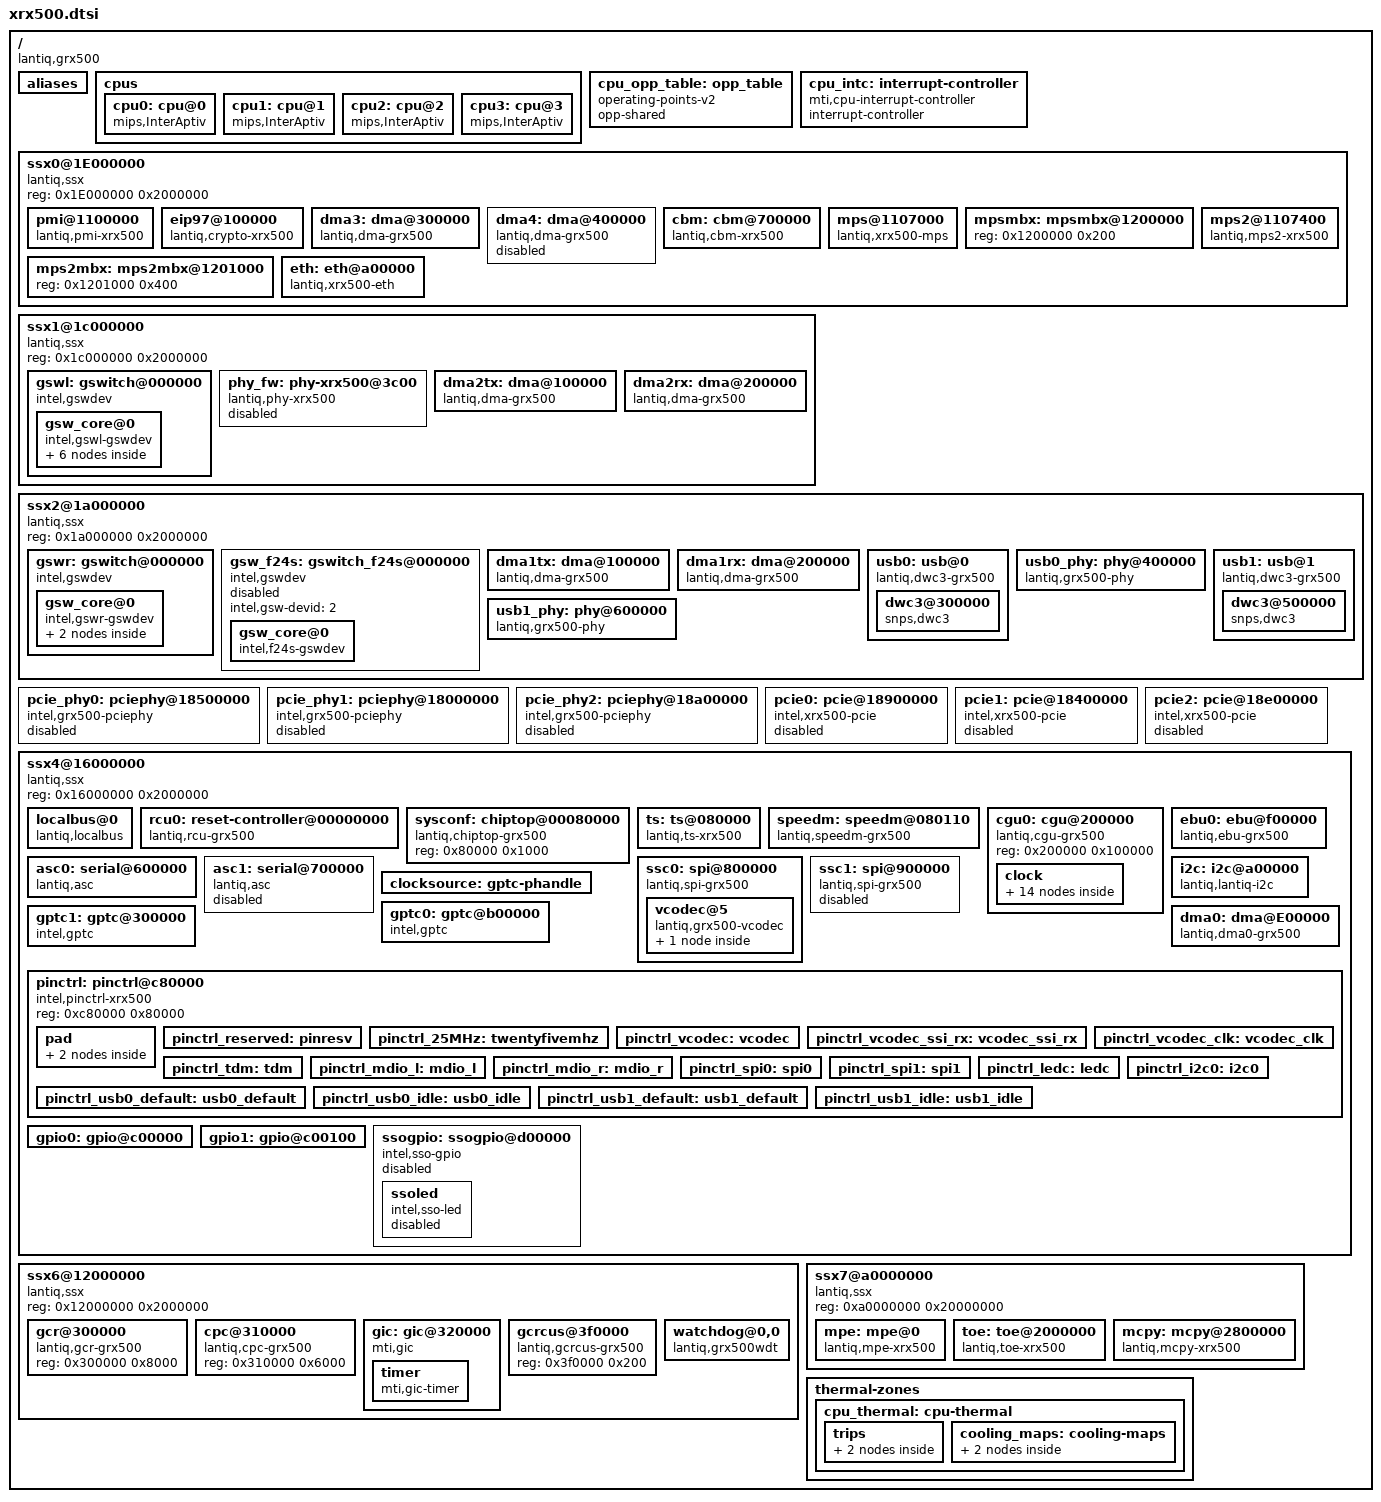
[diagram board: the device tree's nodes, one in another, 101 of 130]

#include <dt-bindings/thermal/thermal.h>

/ {
	#address-cells = <1>;
	#size-cells = <1>;
	compatible = "lantiq,grx500","lantiq,xrx500";

	aliases {
		serial0 = &asc0;
		serial1 = &asc1;
		dma0    = &dma0;
		dma1    = &dma1tx;
		dma2    = &dma1rx;
		dma3    = &dma2tx;
		dma4    = &dma2rx;
		dma5    = &dma3;
		dma6    = &dma4;
		pcie0   = &pcie0;
		pcie1   = &pcie1;
		pcie2   = &pcie2;
		usb0	= &usb0;
		usb1	= &usb1;
		spi1	= &ssc1;
		timer0  = &gptc0;
		timer1  = &gptc1;
		gpio0   = &gpio0;
		gpio1	= &gpio1;
		pciephy0= &pcie_phy0;
		pciephy1= &pcie_phy1;
		pciephy2= &pcie_phy2;
	};

	cpus {
		#address-cells = <1>;
		#size-cells = <0>;

		cpu0: cpu@0 {
			device_type = "cpu";
			compatible = "mips,InterAptiv";
			default-OS = "LINUX";
			clocks = <&cpuclk>;
			clock-names = "cpu";
			clock-latency = <500000>; /* transition latency in ns */
			reg = <0>;
			operating-points-v2 = <&cpu_opp_table>;
			cooling-min-level = <0>;
			cooling-max-level = <2>;
			#cooling-cells = <2>; /* min followed by max */
		};

		cpu1: cpu@1 {
			device_type = "cpu";
			compatible = "mips,InterAptiv";
			default-OS = "LINUX";
			reg = <1>;
			interrupt-parent = <&gic>;
			interrupts = <GIC_SHARED 87 IRQ_TYPE_EDGE_RISING>;
			vmb-fw-ipi = <20>;
			operating-points-v2 = <&cpu_opp_table>;
		};

		cpu2: cpu@2 {
			device_type = "cpu";
			compatible = "mips,InterAptiv";
			default-OS = "LINUX";
			reg = <2>;
			interrupt-parent = <&gic>;
			interrupts = <GIC_SHARED 88 IRQ_TYPE_EDGE_RISING>;
			vmb-fw-ipi = <21>;
			operating-points-v2 = <&cpu_opp_table>;
		};

		cpu3: cpu@3 {
			device_type = "cpu";
			compatible = "mips,InterAptiv";
			default-OS = "LINUX";
			reg = <3>;
			interrupt-parent = <&gic>;
			interrupts = <GIC_SHARED 110 IRQ_TYPE_EDGE_RISING>;
			vmb-fw-ipi = <85>;
			operating-points-v2 = <&cpu_opp_table>;
		};
	};

	cpu_opp_table: opp_table {
		compatible = "operating-points-v2";
		opp-shared;
		/* Define OPPs into a board DTS file */
	};

	cpu_intc: interrupt-controller {
		#address-cells = <0>;
		#interrupt-cells = <1>;
		interrupt-controller;
		compatible = "mti,cpu-interrupt-controller";
	};

	ssx0@1E000000 {
		#address-cells = <1>;
		#size-cells = <1>;
		compatible = "lantiq,ssx", "simple-bus";
		reg = <0x1E000000 0x2000000>;
		ranges = <0x0 0x1E000000 0x02000000>;

		pmi@1100000 {
			compatible = "lantiq,pmi-xrx500";
			reg = <0x1100000 0x100>;
			interrupt-parent = <&gic>;
			interrupts = <GIC_SHARED 94 IRQ_TYPE_LEVEL_HIGH>;
		};

		eip97@100000 {
			compatible = "lantiq,crypto-xrx500";
			reg = <0x100000 0x100000>;
			interrupt-parent = <&gic>;
			interrupts = <GIC_SHARED 89 IRQ_TYPE_LEVEL_HIGH>,
				<GIC_SHARED 90 IRQ_TYPE_LEVEL_HIGH>,
				<GIC_SHARED 91 IRQ_TYPE_LEVEL_HIGH>;
			clocks = <&clkgate1 GATE_EIP97_CLK>;
		};

		dma3: dma@300000 {
			compatible = "lantiq,dma-grx500";
			reg = <0x300000 0x100000>;
			interrupt-parent = <&gic>;
			interrupts = <GIC_SHARED 69 IRQ_TYPE_LEVEL_HIGH>;
			lantiq,dma-pkt-arb = <2>; /* 0 - burst, 1 - mulitburst, 2 - pkt */
			lantiq,dma-burst = <16>; /* 2, 4, 8, 16 */
			lantiq,dma-polling-cnt = <24>;
			lantiq,dma-chan-fc = <0>;
			lantiq,dma-desc-fod = <0>;
			lantiq,dma-desc-in-sram = <1>;
			lantiq,dma-drb = <0>;
			lantiq,dma-byte-en = <1>;
			lantiq,dma-txendi =<3>;
			lantiq,dma-rxendi =<3>;
			lantiq,budget = <20>;
			clocks = <&clkgate1 GATE_TOE_CLK>;
		};

		dma4: dma@400000 {
			status = "disabled";
			compatible = "lantiq,dma-grx500";
			reg = <0x400000 0x100000>;
			interrupt-parent = <&gic>;
			interrupts = <GIC_SHARED 70 IRQ_TYPE_LEVEL_HIGH>;
			lantiq,dma-pkt-arb = <2>; /* 0 - burst, 1 - mulitburst, 2 - pkt */
			lantiq,dma-burst = <16>; /* 2, 4, 8, 16 */
			lantiq,dma-polling-cnt = <24>;
			lantiq,dma-chan-fc = <0>;
			lantiq,dma-desc-fod = <0>;
			lantiq,dma-desc-in-sram = <0>;
			lantiq,dma-drb = <0>;
			lantiq,dma-txendi =<3>;
			lantiq,dma-rxendi =<3>;
		};

		cbm: cbm@700000 {
			status = "ok";
			compatible = "lantiq,cbm-xrx500";
			reg = < 0x700000 0x1000   /*TMU*/
				0x710000 0x10000 /*CBM*/
				0x720000 0x4000 /*QIDT*/
				0x730000 0x14000 /*SBIM*/
				0x750000 0x400 /*QEQCNTR*/
				0x750800 0x400 /*QDQCNTR*/
				0x760000 0x10000 /*LS*/
				0x780000 0x20000 /*CBM EQM*/
				0x7C0000 0x30000 /*CBM DQM*/
				0x800000 0x100000 /*FSQM0*/
				0x900000 0x100000 /*FSQM1*/
				0x500000 0x100000 /*CBM DMA DESC*/
				>;
				interrupt-parent = <&gic>;
				interrupts = <GIC_SHARED 174 IRQ_TYPE_LEVEL_HIGH>,
					<GIC_SHARED 178 IRQ_TYPE_LEVEL_HIGH>,
					<GIC_SHARED 179 IRQ_TYPE_LEVEL_HIGH>,
					<GIC_SHARED 180 IRQ_TYPE_LEVEL_HIGH>,
					<GIC_SHARED 181 IRQ_TYPE_LEVEL_HIGH>;
				clocks = <&pll0aclk CBM_CLK>, <&clkgate1 GATE_CBM_CLK>;
				clock-names = "freq", "cbm";
				intel,highprio-lan = <1>;
		};

		mps@1107000 {
			compatible = "lantiq,xrx500-mps";
			reg = <0x1107000 0x400>;
			interrupt-parent = <&gic>;
			interrupts = <GIC_SHARED 146 IRQ_TYPE_LEVEL_HIGH>, <GIC_SHARED 147 IRQ_TYPE_LEVEL_HIGH>;
			lantiq,mbx = <&mpsmbx>;
			pinctrl-names = "pcm";
			pinctrl-0 = <&pinctrl_tdm>;
		};

		mpsmbx: mpsmbx@1200000 {
			reg = <0x1200000 0x200>;
		};

		mps2@1107400 {
			compatible = "lantiq,mps2-xrx500";
			reg = <0x1107400 0x400>;
			interrupt-parent = <&gic>;
			interrupts = <GIC_SHARED 215 IRQ_TYPE_LEVEL_HIGH>, <GIC_SHARED 216 IRQ_TYPE_LEVEL_HIGH>;
			lantiq,mbx = <&mps2mbx>;
		};

		mps2mbx: mps2mbx@1201000 {
			reg = <0x1201000 0x400>;
		};

		eth:eth@a00000{
			#address-cells = <1>;
			#size-cells = <0>;
			#cooling-cells = <2>;
			compatible = "lantiq,xrx500-eth";
			lantiq,eth-rx-csum-offload = <1>;
			lantiq,eth-switch-mode = <2>;
		};
	};

	ssx1@1c000000 {
		#address-cells = <1>;
		#size-cells = <1>;
		compatible = "lantiq,ssx", "simple-bus";
		reg = <0x1c000000 0x2000000>;
		ranges = <0x0 0x1c000000 0x02000000>;

		gswl: gswitch@000000 {
			#address-cells = <1>;
			#size-cells = <1>;
			compatible = "intel,gswdev";
			intel,gsw-devid = <0>;
			reg = <0x000000 0x3000>;
			ranges = <0x0 0x00000000 0x00003000>;
			pinctrl-names = "default";
			gsw_core@0 {
				#address-cells = <1>;
				#size-cells = <1>;
				compatible = "intel,gswl-gswdev";
				num_resources = <1>;
				reg = <0x000000 0x3000>;
				ranges = <0x0 0x00000000 0x00003000>;
				interrupt-parent = <&gic>;
				interrupts = <GIC_SHARED 48 IRQ_TYPE_LEVEL_HIGH>;
				clocks = <&pll0bclk GSWIP_CLK>, <&clkgate1 GATE_GSWIP_CLK>;
				clock-names = "freq", "gate";
				intel,gsw-globalpce-rules = <512>;
				intel,gsw-devid = <0>;
				gswl_mdio: gsw_mdio {
					#address-cells = <1>;
					#size-cells = <0>;
					phy2: ethernet-phy@2 {
						reg = <2>;
						compatible = "ethernet-phy-idd565.a408",
						             "ethernet-phy-ieee802.3-c22";
					};
					phy3: ethernet-phy@3 {
						reg = <3>;
						compatible = "ethernet-phy-idd565.a408",
						             "ethernet-phy-ieee802.3-c22";
					};
					phy4: ethernet-phy@4 {
						reg = <4>;
						compatible = "ethernet-phy-idd565.a408",
						             "ethernet-phy-ieee802.3-c22";
					};
					phy5: ethernet-phy@5 {
						reg = <5>;
						compatible = "ethernet-phy-idd565.a408",
						             "ethernet-phy-ieee802.3-c22";
					};
					phy6: ethernet-phy@6 {
						reg = <6>;
						compatible = "ethernet-phy-idd565.a408",
						             "ethernet-phy-ieee802.3-c22";
					};
				};
			};
		};

		phy_fw: phy-xrx500@3c00 {
			status = "disabled";
			compatible = "lantiq,phy-xrx500";
			reg = <0x3c00 0x400>;
			resets = <&rcu0 0x10 29>, <&rcu0 0x10 28>,
				 <&rcu0 0x10 26>, <&rcu0 0x10 25>,
				 <&rcu0 0x10 31>;
			reset-names = "phy0", "phy1", "phy2", "phy3", "phy4";
		};

		dma2tx: dma@100000 {
			compatible = "lantiq,dma-grx500";
			reg = <0x100000 0x100000>;
			interrupt-parent = <&gic>;
			interrupts = <GIC_SHARED 67 IRQ_TYPE_LEVEL_HIGH>;
			lantiq,dma-pkt-arb = <2>; /* 0 - burst, 1 - mulitburst, 2 - pkt */
			lantiq,dma-burst = <16>; /* 2, 4, 8, 16 */
			lantiq,dma-polling-cnt = <24>;
			lantiq,dma-chan-fc = <1>;
			lantiq,dma-desc-fod = <1>;
			lantiq,dma-desc-in-sram = <0>;
			lantiq,dma-drb = <0>;
			lantiq,dma-byte-en = <1>;
			lantiq,dma-txendi =<3>;
			lantiq,dma-rxendi =<3>;
			lantiq,budget = <20>;
		};

		dma2rx: dma@200000 {
			compatible = "lantiq,dma-grx500";
			reg = <0x200000 0x100000>;
			interrupt-parent = <&gic>;
			interrupts = <GIC_SHARED 68 IRQ_TYPE_LEVEL_HIGH>;
			lantiq,dma-pkt-arb = <2>; /* 0 - burst, 1 - mulitburst, 2 - pkt */
			lantiq,dma-burst = <16>; /* 2, 4, 8, 16 */
			lantiq,dma-polling-cnt = <24>;
			lantiq,dma-chan-fc = <0>;
			lantiq,dma-desc-fod = <1>;
			lantiq,dma-desc-in-sram = <0>;
			lantiq,dma-drb = <0>;
			lantiq,dma-byte-en = <1>;
			lantiq,dma-txendi =<3>;
			lantiq,dma-rxendi =<3>;
			lantiq,budget = <20>;
		};
	};

	ssx2@1a000000 {
		#address-cells = <1>;
		#size-cells = <1>;
		compatible = "lantiq,ssx", "simple-bus";
		reg = <0x1a000000 0x2000000>;
		ranges = <0x0 0x1a000000 0x02000000>;

		gswr: gswitch@000000 {
			#address-cells = <1>;
			#size-cells = <1>;
			compatible = "intel,gswdev";
			intel,gsw-devid = <1>;
			reg = <0x000000 0x3000>;
			ranges = <0x0 0x00000000 0x00003000>;
			pinctrl-names = "default";
			pinctrl-0 = <&pinctrl_mdio_r>;
			gsw_core@0 {
				#address-cells = <1>;
				#size-cells = <1>;
				compatible = "intel,gswr-gswdev";
				num_resources = <1>;
				reg = <0x000000 0x3000>;
				ranges = <0x0 0x00000000 0x00003000>;
				interrupt-parent = <&gic>;
				interrupts = <GIC_SHARED 45 IRQ_TYPE_LEVEL_HIGH>;
				clocks = <&pll0bclk PAE_CLK>, <&clkgate1 GATE_PAE_CLK>;
				clock-names = "freq", "gate";
				intel,gsw-globalpce-rules = <512>;
				intel,gsw-devid = <1>;
				gswr_mdio: gsw_mdio {
					#address-cells = <1>;
					#size-cells = <0>;
					phy1: ethernet-phy@1 {
						reg = <1>;
						compatible = "ethernet-phy-idd565.a408",
						             "ethernet-phy-ieee802.3-c22";
					};
				};
			};
		};

		gsw_f24s: gswitch_f24s@000000 {
			compatible = "intel,gswdev";
			intel,gsw-devid = <2>;
			status = "disabled";
			gsw_core@0 {
				compatible = "intel,f24s-gswdev";
				num_resources = <0>;
				intel,gsw_ext-switch = <1>; /* <0> - MMIO SWITCH, <1> - EXTERNAL SWITCH */
				master-mdio = <&gswr_mdio>;
				intel,gsw_ext-phyid = <0x1f>;
				intel,gsw_ext-baseaddr = <0xe000>;
				intel,gsw_ext-sgmiibaseaddr = <0xD000>;
				intel,gsw-globalpce-rules = <128>;
				intel,gsw-devid = <2>;
			};
		};

		dma1tx: dma@100000 {
			compatible = "lantiq,dma-grx500";
			reg = <0x100000 0x100000>;
			interrupt-parent = <&gic>;
			interrupts = <GIC_SHARED 65 IRQ_TYPE_LEVEL_HIGH>;
			lantiq,dma-pkt-arb = <2>; /* 0 - burst, 1 - mulitburst, 2 - pkt */
			lantiq,dma-burst = <16>; /* 2, 4, 8, 16 */
			lantiq,dma-polling-cnt = <108>;
			lantiq,dma-chan-fc = <1>;
			lantiq,dma-desc-fod = <1>;
			lantiq,dma-desc-in-sram = <1>; /* A11 - 0, A21 - 1*/
			lantiq,dma-drb = <0>;
			lantiq,dma-byte-en = <1>;
			lantiq,budget = <20>;
			lantiq,dma-lab-cnt = <2>; /* 0, 1, 2, 3 */
			lantiq,dma-txendi =<3>;
			lantiq,dma-rxendi =<3>;
		};

		dma1rx: dma@200000 {
			compatible = "lantiq,dma-grx500";
			reg = <0x200000 0x100000>;
			interrupt-parent = <&gic>;
			interrupts = <GIC_SHARED 66 IRQ_TYPE_LEVEL_HIGH>;
			lantiq,dma-pkt-arb = <2>; /* 0 - burst, 1 - mulitburst, 2 - pkt */
			lantiq,dma-burst = <16>; /* 2, 4, 8, 16 */
			lantiq,dma-polling-cnt = <24>;
			lantiq,dma-chan-fc = <0>;
			lantiq,dma-desc-fod = <1>;
			lantiq,dma-desc-in-sram = <0>;
			lantiq,dma-drb = <0>;
			lantiq,dma-byte-en = <0>;
			lantiq,dma-txendi =<3>;
			lantiq,dma-rxendi =<3>;
			lantiq,budget = <20>;
		};

		usb0:usb@0 {
			compatible = "lantiq,dwc3-grx500";
			reg = <0x18 0x4>;
			#address-cells = <1>;
			#size-cells = <1>;
			intel,syscon = <&sysconf>;
			ranges;
			dwc3@300000 {
				compatible = "snps,dwc3";
				reg = <0x300000 0x10000>;
				interrupt-parent = <&gic>;
				interrupts = <GIC_SHARED 54 IRQ_TYPE_LEVEL_HIGH>;
				snps,dis_rxdet_inp3_quirk;
				dr_mode = "host";
				phys = <&usb0_phy>;
				phy-names = "usb3-phy";
			};
		};

		usb0_phy:phy@400000 {
			compatible ="lantiq,grx500-phy";
			reg = <0x400000 0x10000>;
			interrupt-parent = <&gic>;
			interrupts = <GIC_SHARED 53 IRQ_TYPE_LEVEL_HIGH>;
			resets = <&rcu0 0x48 4>;
			reset-names = "phy";
			clocks = <&clkgate1 GATE_USB0_CLK>;
			#phy-cells = <0>;
			pinctrl-names = "default","idle";
			pinctrl-0 = <&pinctrl_usb0_default>;
			pinctrl-1 = <&pinctrl_usb0_idle>;
		};

		usb1:usb@1 {
			compatible = "lantiq,dwc3-grx500";
			reg = <0x34 0x4>;
			#address-cells = <1>;
			#size-cells = <1>;
			intel,syscon = <&sysconf>;
			ranges;
			dwc3@500000 {
				compatible = "snps,dwc3";
				reg = <0x500000 0x10000>;
				interrupt-parent = <&gic>;
				interrupts = <GIC_SHARED 83 IRQ_TYPE_LEVEL_HIGH>;
				snps,dis_rxdet_inp3_quirk;
				dr_mode = "host";
				phys = <&usb1_phy>;
				phy-names = "usb3-phy";
			};
		};

		usb1_phy:phy@600000 {
			compatible ="lantiq,grx500-phy";
			reg = <0x600000 0x10000>;
			interrupt-parent = <&gic>;
			interrupts = <GIC_SHARED 50 IRQ_TYPE_LEVEL_HIGH>;
			resets = <&rcu0 0x48 5>;
			reset-names = "phy";
			clocks = <&clkgate1 GATE_USB1_CLK>;
			#phy-cells = <0>;
			pinctrl-names = "default","idle";
			pinctrl-0 = <&pinctrl_usb1_default>;
			pinctrl-1 = <&pinctrl_usb1_idle>;
		};
	};

	pcie_phy0: pciephy@18500000 {
		status = "disabled";
		compatible = "intel,grx500-pciephy";
		#address-cells = <1>;
		#size-cells = <1>;
		#phy-cells = <0>;
		reg = <
			0x18500000 0x100000 /* PCIe PHY Reg */
		>;
		reg-names = "phy";
		intel,ssc-syscon = <&cgu0>;
		intel,ssc-enable = <0>;
		intel,syscon =<&sysconf>;
		resets = <&rcu0 0x10 12>;
		reset-names = "phy";
	};

	pcie_phy1: pciephy@18000000 {
		status = "disabled";
		compatible = "intel,grx500-pciephy";
		#address-cells = <1>;
		#size-cells = <1>;
		#phy-cells = <0>;
		reg = <
			0x18000000 0x100000 /* PCIe PHY Reg */
		>;
		reg-names = "phy";
		intel,ssc-syscon = <&cgu0>;
		intel,ssc-enable = <0>;
		intel,syscon =<&sysconf>;
		resets = <&rcu0 0x10 13>;
		reset-names = "phy";
	};

	pcie_phy2: pciephy@18a00000 {
		status = "disabled";
		compatible = "intel,grx500-pciephy";
		#address-cells = <1>;
		#size-cells = <1>;
		#phy-cells = <0>;
		reg = <
			0x18a00000 0x100000 /* PCIe PHY Reg */
		>;
		reg-names = "phy";
		intel,ssc-syscon = <&cgu0>;
		intel,ssc-enable = <0>;
		intel,syscon =<&sysconf>;
		resets = <&rcu0 0x10 10>;
		reset-names = "phy";
	};

	pcie0:pcie@18900000 {
		status = "disabled";
		compatible = "intel,xrx500-pcie";
		device_type = "pci";
		#address-cells = <3>;
		#size-cells = <2>;
		reg = <
			0x18900000 0x100000 /* RC controller */
			0xbb000000 0x800000 /* Cfg */
			0x18800000 0x100000 /* App logic */
			0x18600000 0x100000 /* MSI addr space */
			0x18700000 0x100000 /* MSI PIC */
		>;
		reg-names = "csr", "cfg", "app", "msi", "pic";
		linux,pci-domain = <0>;
		max-link-speed = <2>;
		bus-range = <0x00 0x08>;
		interrupt-parent = <&gic>;
		interrupts = <GIC_SHARED 128 IRQ_TYPE_EDGE_RISING>,
			<GIC_SHARED 129 IRQ_TYPE_EDGE_RISING>,
			<GIC_SHARED 130 IRQ_TYPE_EDGE_RISING>,
			<GIC_SHARED 131 IRQ_TYPE_EDGE_RISING>,
			<GIC_SHARED 132 IRQ_TYPE_EDGE_RISING>,
			<GIC_SHARED 133 IRQ_TYPE_EDGE_RISING>,
			<GIC_SHARED 134 IRQ_TYPE_EDGE_RISING>,
			<GIC_SHARED 135 IRQ_TYPE_EDGE_RISING>,
			<GIC_SHARED 152 IRQ_TYPE_LEVEL_HIGH>;
		interrupt-names = "msi0", "msi1", "msi2", "msi3", "msi4", "msi5", "msi6", "msi7", "ir";
		#interrupt-cells = <1>;
		interrupt-map-mask = <0 0 0 0x7>;
		interrupt-map = <0 0 0 1 &gic  GIC_SHARED 136 IRQ_TYPE_LEVEL_HIGH>,
				<0 0 0 2 &gic  GIC_SHARED 137 IRQ_TYPE_LEVEL_HIGH>,
				<0 0 0 3 &gic  GIC_SHARED 138 IRQ_TYPE_LEVEL_HIGH>,
				<0 0 0 4 &gic  GIC_SHARED 139 IRQ_TYPE_LEVEL_HIGH>;
		ranges = <0x02000000 0 0xb8000000 0xb8000000 0 0x03000000    /* Non-pretechable memory 32bit */
			  0x01000000 0 0xbb800000 0xbb800000 0 0x00010000    /* Downsream I/O */
			 >;

		intel,syscon = <&sysconf>;
		intel,inbound-shift = <5>;
		intel,outbound-shift = <4>;
		intel,iatu = <0>;
		clocks = <&clkgate2 GATE_PCIE0_CLK>;
		clock-names ="ctl";
		phys = <&pcie_phy0>;
		phy-names = "phy";
	};

	pcie1:pcie@18400000 {
		status = "disabled";
		compatible = "intel,xrx500-pcie";
		device_type = "pci";
		#address-cells = <3>;
		#size-cells = <2>;
		reg = <
			0x18400000 0x100000 /* RC controller */
			0xb7000000 0x800000 /* Cfg*/
			0x18300000 0x100000 /* App logic */
			0x18100000 0x100000 /* MSI phy space */
			0x18200000 0x100000 /* MSI PIC */
		>;
		reg-names = "csr", "cfg", "app", "msi", "pic";
		linux,pci-domain = <1>;
		max-link-speed = <2>;
		bus-range = <0x00 0x08>;
		interrupt-parent = <&gic>;
		interrupts = <GIC_SHARED 37 IRQ_TYPE_EDGE_RISING>,
			<GIC_SHARED 38 IRQ_TYPE_EDGE_RISING>,
			<GIC_SHARED 39 IRQ_TYPE_EDGE_RISING>,
			<GIC_SHARED 40 IRQ_TYPE_EDGE_RISING>,
			<GIC_SHARED 41 IRQ_TYPE_EDGE_RISING>,
			<GIC_SHARED 42 IRQ_TYPE_EDGE_RISING>,
			<GIC_SHARED 43 IRQ_TYPE_EDGE_RISING>,
			<GIC_SHARED 44 IRQ_TYPE_EDGE_RISING>,
			<GIC_SHARED 49 IRQ_TYPE_LEVEL_HIGH>;
		interrupt-names = "msi0", "msi1", "msi2", "msi3", "msi4", "msi5", "msi6", "msi7", "ir";
		#interrupt-cells = <1>;
		interrupt-map-mask = <0 0 0 0x7>;
		interrupt-map = <0 0 0 1 &gic  GIC_SHARED 9 IRQ_TYPE_LEVEL_HIGH>,
				<0 0 0 2 &gic  GIC_SHARED 10 IRQ_TYPE_LEVEL_HIGH>,
				<0 0 0 3 &gic  GIC_SHARED 11 IRQ_TYPE_LEVEL_HIGH>,
				<0 0 0 4 &gic  GIC_SHARED 12 IRQ_TYPE_LEVEL_HIGH>;
		ranges = <0x02000000 0 0xb4000000 0xb4000000 0 0x03000000    /* Non-pretechable memory 32bit */
			  0x01000000 0 0xb7800000 0xb7800000 0 0x00010000    /* Downsream I/O */
			 >;

		intel,syscon = <&sysconf>;
		intel,inbound-shift = <9>;
		intel,outbound-shift = <8>;
		intel,iatu = <0>;
		clocks = <&clkgate2 GATE_PCIE1_CLK>;
		clock-names ="ctl";
		phys = <&pcie_phy1>;
		phy-names = "phy";
	};

	pcie2:pcie@18e00000 {
		status = "disabled";
		compatible = "intel,xrx500-pcie";
		#address-cells = <3>;
		#size-cells = <2>;
		device_type = "pci";
		reg = <
			0x18e00000 0x100000 /* RC controller */
			0xbf000000 0x800000 /* Cfg*/
			0x18d00000 0x100000 /* App logic */
			0x18b00000 0x100000 /* MSI addr space */
			0x18c00000 0x100000 /* MSI PIC */
		>;
		reg-names = "csr", "cfg", "app", "msi", "pic";
		linux,pci-domain = <2>;
		max-link-speed = <2>;
		bus-range = <0x00 0x08>;
		interrupt-parent = <&gic>;
		interrupts = <GIC_SHARED 24 IRQ_TYPE_EDGE_RISING>,
			<GIC_SHARED 25 IRQ_TYPE_EDGE_RISING>,
			<GIC_SHARED 26 IRQ_TYPE_EDGE_RISING>,
			<GIC_SHARED 27 IRQ_TYPE_EDGE_RISING>,
			<GIC_SHARED 28 IRQ_TYPE_EDGE_RISING>,
			<GIC_SHARED 29 IRQ_TYPE_EDGE_RISING>,
			<GIC_SHARED 30 IRQ_TYPE_EDGE_RISING>,
			<GIC_SHARED 31 IRQ_TYPE_EDGE_RISING>,
			<GIC_SHARED 55 IRQ_TYPE_LEVEL_HIGH>;
		interrupt-names = "msi0", "msi1", "msi2", "msi3", "msi4", "msi5", "msi6", "msi7", "ir";
		#interrupt-cells = <1>;
		interrupt-map-mask = <0 0 0 0x7>;
		interrupt-map = <0 0 0 1 &gic  GIC_SHARED 155 IRQ_TYPE_LEVEL_HIGH>,
				<0 0 0 2 &gic  GIC_SHARED 156 IRQ_TYPE_LEVEL_HIGH>,
				<0 0 0 3 &gic  GIC_SHARED 157 IRQ_TYPE_LEVEL_HIGH>,
				<0 0 0 4 &gic  GIC_SHARED 158 IRQ_TYPE_LEVEL_HIGH>;
		ranges = <0x02000000 0 0xbc000000 0xbc000000 0 0x03000000    /* Non-pretechable memory 32bit */
			  0x01000000 0 0xbf800000 0xbf800000 0 0x00010000    /* Downsream I/O */
			 >;
		intel,syscon = <&sysconf>;
		intel,inbound-shift = <13>;
		intel,outbound-shift = <12>;
		intel,iatu = <0>;
		clocks = <&clkgate2 GATE_PCIE2_CLK>;
		clock-names ="ctl";
		phys = <&pcie_phy2>;
		phy-names = "phy";
	};

	ssx4@16000000 {
		#address-cells = <1>;
		#size-cells = <1>;
		compatible = "lantiq,ssx", "simple-bus";
		reg = <0x16000000 0x2000000>;
		ranges = <0x0 0x16000000 0x02000000>;

		localbus@0 {
			#address-cells = <2>;
			#size-cells = <1>;
			ranges = <0 0 0x1400000 0xc00000 /* addrsel0 */
			1 0 0x1c00000 0x100000>; /* addsel1 */
			compatible = "lantiq,localbus", "simple-bus";
		};

		rcu0: reset-controller@00000000 {
			compatible = "lantiq,rcu-grx500", "syscon";
			reg = <0x000000 0x80000>;
			#reset-cells = <2>;
			intel,global-reset = <&rcu0 0x10 30>;
		};

		sysconf: chiptop@00080000 {
			compatible = "lantiq,chiptop-grx500", "syscon", "simple-mfd";
			reg = <0x80000 0x1000>;
			#reset-cells = <1>;
		};

		ts: ts@080000 {
			#thermal-sensor-cells = <0>;
			compatible = "lantiq,ts-xrx500";
			interrupt-parent = <&gic>;
			interrupts = <GIC_SHARED 19 IRQ_TYPE_LEVEL_HIGH>;
			lantiq,numofsensors = <0x2>;
			intel,syscon = <&sysconf>;
		};

		speedm: speedm@080110 {
			compatible = "lantiq,speedm-grx500" , "lantiq,speedm-xrx500"; 
			reg = <0x080110 0x0C>;
			lantiq,thresholds_lvt = <1 10000 1 10000 1 10000>;
			lantiq,thresholds_svt = <1000 3350 3351 4000 4001 8000>;
			lantiq,sample_rate_svt = <255>;
			lantiq,sample_rate_lvt = <255>;
		};

		cgu0: cgu@200000 {
			#address-cells = <1>;
			#size-cells = <1>;
			compatible = "lantiq,cgu-grx500", "syscon";
			reg = <0x200000 0x100000>;

			clock {
				#address-cells = <1>;
				#size-cells = <0>;

				osc0: osc0 {
					#clock-cells = <0>;
					compatible = "fixed-clock";
					clock-frequency = <40000000>;
					clock-output-names = "osc40M";
				};

				pll0a: pll0a {
					#clock-cells = <0>;
					compatible = "fixed-factor-clock";
					clock-mult = <0x3C>;
					clock-div = <1>;
					clocks = <&osc0>;
					clock-output-names = "pll0a";
				};

				pll0b: pll0b {
					#clock-cells = <0>;
					compatible = "fixed-factor-clock";
					clock-mult = <0x32>;
					clock-div = <1>;
					clocks = <&osc0>;
					clock-output-names = "pll0b";
				};

				pll3: pll3 {
					#clock-cells = <0>;
					compatible = "fixed-factor-clock";
					clock-mult = <0x64>;
					clock-div = <1>;
					clocks = <&osc0>;
					clock-output-names = "lcpll3";
				};

				pll0aclk: pll0aclk {
					#clock-cells = <1>;
					compatible = "lantiq, grx500-pll0a-output-clk";
					clocks = <&pll0a>;
					reg = <0x8>;
					clock-output-names = "cbmclk", "ngiclk", "ssx4clk", "cpu0clk";
				};

				pll0bclk: pll0bclk {
					#clock-cells = <1>;
					compatible = "lantiq, grx500-pll0b-output-clk";
					clocks = <&pll0b>;
					reg = <0x38>;
					clock-output-names = "paeclk", "gswipclk", "ddrclk", "cpu1clk";
				};

				pcieclk: pcieclk {
					#clock-cells = <0>;
					compatible = "lantiq, grx500-pcie-clk";
					clocks = <&pll3>;
					reg = <0x98>;
					clock-output-names = "pcieclk";
				};

				cpuclk: cpuclk {
					#clock-cells = <0>;
					compatible = "lantiq, grx500-cpu-clk";
					clocks = <&pll0aclk CPU0_CLK>, <&pll0bclk CPU1_CLK>;
					reg = <0x8>;
					clock-output-names = "cpu";
				};

				clkgate0: clkgate0 {
					#clock-cells = <1>;
					compatible = "lantiq, grx500-gate0-clk";
					reg = <0x114>;
					clock-output-names = "gate_xbar0", "gate_xbar1", "gate_xbar2",
						"gate_xbar3", "gate_xbar6", "gate_xbar7";
				};

				clkgate1: clkgate1 {
					#clock-cells = <1>;
					compatible = "lantiq, grx500-gate1-clk";
					reg = <0x120>;
					clock-output-names = "gate_vcodec", "gate_dma0", "gate_usb0",
						"gate_spi1", "gate_spi0", "gate_cbm", "gate_ebu",
						"gate_sso", "gate_gptc0", "gate_gptc1", "gate_gptc2",
						"gate_urt", "gate_eip97", "gate_eip123", "gate_toe",
						"gate_mpe", "gate_tdm", "gate_pae", "gate_usb1", "gate_gswip";
				};

				clkgate2: clkgate2 {
					#clock-cells = <1>;
					compatible = "lantiq, grx500-gate2-clk";
					reg = <0x130>;
					clock-output-names = "gate_pcie0", "gate_pcie1", "gate_pcie2";
				};

				voiceclk: voiceclk {
					#clock-cells = <0>;
					compatible = "lantiq, grx500-voice-clk";
					clock-frequency = <8192000>;
					reg = <0xc4>;
					clock-output-names = "VOICE_CLK";
				};

				afeclk: afeclk {
					#clock-cells = <0>;
					compatible = "fixed-clock";
					clock-frequency = <8000>;
					clock-output-names = "afeclk";
				};

				i2cclk: i2cclk {
					#clock-cells = <0>;
					compatible = "lantiq, grx500-gate-dummy-clk";
					clock-output-names = "gate_i2c";
				};
			};
		};

		ebu0: ebu@f00000 {
			compatible = "lantiq,ebu-grx500", "lantiq,ebu-xrx500";
			reg = <0xf00000 0x100000>,
				<0x1000000 0x100000>;
			reg-names = "ebunand_reg", "hsnand_reg";
			clocks = <&clkgate1 GATE_EBU_CLK>;
		};

		asc0: serial@600000 {
			compatible = "lantiq,asc";
			reg = <0x600000 0x100000>;
			interrupt-parent = <&gic>;
			interrupts = <GIC_SHARED 103 IRQ_TYPE_LEVEL_HIGH>,
				<GIC_SHARED 105 IRQ_TYPE_LEVEL_HIGH>,
				<GIC_SHARED 106 IRQ_TYPE_LEVEL_HIGH>;
			clocks = <&pll0aclk SSX4_CLK>, <&clkgate1 GATE_URT_CLK>;
			clock-names = "freq", "asc";
		};

		asc1: serial@700000 {
			compatible = "lantiq,asc";
			reg = <0x700000 0x100000>;
			interrupt-parent = <&gic>;
			interrupts = <GIC_SHARED 76 IRQ_TYPE_LEVEL_HIGH>,
				<GIC_SHARED 78 IRQ_TYPE_LEVEL_HIGH>,
				<GIC_SHARED 79 IRQ_TYPE_LEVEL_HIGH>;
			clocks = <&pll0aclk SSX4_CLK>, <&clkgate1 GATE_URT_CLK>;
			clock-names = "freq", "asc";
			status = "disabled";
		};

		ssc0: spi@800000 {
			compatible = "lantiq,spi-grx500","lantiq,spi-lantiq-ssc";
			reg = <0x800000 0x400>;
			interrupt-parent = <&gic>;
			interrupts = <GIC_SHARED 14 IRQ_TYPE_EDGE_RISING>,
				<GIC_SHARED 15 IRQ_TYPE_EDGE_RISING>,
				<GIC_SHARED 16 IRQ_TYPE_EDGE_RISING>;
			interrupt-names = "spi_rx", "spi_tx", "spi_err";
			#address-cells = <1>;
			#size-cells = <0>;
			clocks = <&pll0aclk SSX4_CLK>, <&clkgate1 GATE_SPI0_CLK>;
			clock-names = "freq", "spi";
			vcodec@5 {
				compatible = "lantiq,grx500-vcodec";
				spi-max-frequency = <8000000>;
				reg = <5>;
				resets = <&rcu0 0x48 0>;
				reset-names = "vcodec";
				interrupts = <GIC_SHARED 209 IRQ_TYPE_LEVEL_HIGH>;
				interrupt-parent = <&gic>;
				clocks = <&voiceclk>, <&clkgate1 GATE_V_CODEC_CLK>;
				clock-names = "clkout0", "vcodec";
				pinctrl-names = "default";
				pinctrl-0 = <&pinctrl_vcodec &pinctrl_vcodec_ssi_rx &pinctrl_vcodec_clk>;
				slic: slic@0 {
					compatible = "lantiq,slic200";
					dcdc_type = "IBB";
				};
			};
		};

		ssc1: spi@900000 {
			compatible = "lantiq,spi-grx500","lantiq,spi-ssc";
			reg = <0x900000 0x400>;
			interrupt-parent = <&gic>;
			interrupts = <GIC_SHARED 99 IRQ_TYPE_EDGE_RISING>,
				<GIC_SHARED 100 IRQ_TYPE_EDGE_RISING>,
				<GIC_SHARED 101 IRQ_TYPE_EDGE_RISING>;
			#address-cells = <1>;
			#size-cells = <1>;
			lantiq,ssc-port = <1>;
			clocks = <&pll0aclk SSX4_CLK>, <&clkgate1 GATE_SPI1_CLK>;
			clock-names = "freq", "spi";
			pinctrl-names = "default";
			pinctrl-0 = <&pinctrl_spi1 &pinctrl_spi1_cs0>;
			status = "disabled";
		};

		i2c: i2c@a00000 {
			#address-cells = <1>;
			#size-cells = <0>;
			status = "ok";
			compatible = "lantiq,lantiq-i2c";
			reg = <0xa00000 0x10000>;
			interrupt-parent = <&gic>;
			interrupts = <GIC_SHARED 33 IRQ_TYPE_EDGE_RISING>,
				<GIC_SHARED 32 IRQ_TYPE_EDGE_RISING>,
				<GIC_SHARED 23 IRQ_TYPE_EDGE_RISING>,
				<GIC_SHARED 36 IRQ_TYPE_EDGE_RISING>;
			clock-frequency = <100000>;
			clocks = <&pll0aclk SSX4_CLK>, <&i2cclk 0>;
			clock-names = "freq", "i2c";
			pinctrl-names = "default";
			pinctrl-0 = <&pinctrl_i2c0>;
		};

		clocksource: gptc-phandle {
			#gptc-cells = <3>;
		};

		gptc0: gptc@b00000 {
			compatible = "intel,gptc", "lantiq,gptc";
			reg = <0xb00000 0x400>;
			interrupt-parent = <&gic>;
			interrupts = <GIC_SHARED 118 IRQ_TYPE_EDGE_RISING>,
				<GIC_SHARED 120 IRQ_TYPE_EDGE_RISING>,
				<GIC_SHARED 122 IRQ_TYPE_EDGE_RISING>;
			interrupt-names = "tc1a", "tc2a", "tc3a";
			intel,clk = <&clocksource 1 0 1>, <&clocksource 3 1 0>, <&clocksource 0 2 0>;
			clocks = <&pll0aclk SSX4_CLK>, <&clkgate1 GATE_GPTC0_CLK>;
			clock-names = "freq", "gptc";
		};

		gptc1: gptc@300000 {
			compatible = "intel,gptc", "lantiq,gptc";
			reg = <0x300000 0x400>;
			interrupt-parent = <&gic>;
			interrupts = <GIC_SHARED 160 IRQ_TYPE_EDGE_RISING>,
				<GIC_SHARED 162 IRQ_TYPE_EDGE_RISING>,
				<GIC_SHARED 164 IRQ_TYPE_EDGE_RISING>;
			interrupt-names = "tc1a", "tc2a", "tc3a";
			intel,clk = <&clocksource 1 0 0>, <&clocksource 1 1 2>, <&clocksource 4 2 0>;
			clocks =<&pll0aclk SSX4_CLK>, <&clkgate1 GATE_GPTC1_CLK>;
			clock-names = "freq", "gptc";
		};

		dma0: dma@E00000 {
			compatible = "lantiq,dma0-grx500", "lantiq,dma-xway";
			reg = <0xE00000 0x100000>;
			interrupt-parent = <&gic>;
			interrupts = <GIC_SHARED 64 IRQ_TYPE_LEVEL_HIGH>;
			lantiq,desc-num = <256>;
			lantiq,dma-burst = <2>;
			lantiq,dma-polling-cnt = <4>;
			lantiq,dma-drb = <1>;
			lantiq,budget = <20>;
			clocks = <&clkgate1 GATE_DMA0_CLK>;
		};

		pinctrl: pinctrl@c80000 {
			#address-cells = <1>;
			#size-cells = <1>;
			compatible = "intel,pinctrl-xrx500";
			reg = <0xc80000 0x80000>;

			pad {
				#address-cells = <1>;
				#size-cells = <0>;

				pad0: pad@0 {
					reg = <0x0>;
					intel,pinbase = <0>;
					intel,ngpios = <32>;
					intel,pinbank = <0>;
					intel,gpio = <&gpio0>;
				};

				pad1: pad@100 {
					reg = <0x100>;
					intel,pinbase = <32>;
					intel,ngpios = <32>;
					intel,pinbank = <1>;
					intel,gpio = <&gpio1>;
				};
			};

			/* pin configurations */
			/* PINs for nand can not be configured again in xrx500 linux */
			pinctrl_reserved: pinresv {
				intel,pins =  <24>, /* nand cle */ <13>, /*nand ale */
						<49>, /* nand rd */ <48>, /* nand rdy> */
						<51>, /* nand d0 */ <50>, /* nand d1> */
						<52>, /* nand d2 */ <57>, /* nand d3> */
						<56>, /* nand d4 */ <55>, /* nand d5> */
						<54>, /* nand d6 */ <53>, /* nand d7> */
						<23>, /* nand cs1 */ <59>, /* nand wr> */
						<60>, /* nand wp */ <61> /* nand se> */;
				intel,groups = "resv_pins";
				intel,function = "resv_pins";
				intel,mux = <EQBR_MUX_0>;
			};

			pinctrl_25MHz: twentyfivemhz {
				intel,pins =  <3>;
				intel,function = "25Mhz";
				intel,mux = <EQBR_MUX_2>;
				intel,groups = "25Mhz";
			};

			pinctrl_vcodec: vcodec {
				intel,pins =  <1>, /* SSI_RESET */
					      <34>, /* SSI_TX */
					      <36>; /* SSI_CLKI */
				intel,function = "vcodec";
				intel,mux = <EQBR_MUX_2>;
				intel,groups = "vcodec";
			};

			pinctrl_vcodec_ssi_rx: vcodec_ssi_rx {
				intel,pins = <35>; /* SSI_RX */
				intel,function = "vcodec_ssi_rx";
				intel,mux = <EQBR_MUX_2>;
				intel,groups = "vcodec_ssi_rx";
				intel,pullup = <1>;
			};

			pinctrl_vcodec_clk: vcodec_clk {
				intel,pins = <8>;
				intel,function = "vcodec_clk";
				intel,mux = <EQBR_MUX_1>;
				intel,groups = "vcodec_clk";
			};

			pinctrl_tdm: tdm {
				intel,pins =  <28>, /* TDM_FSC */
					      <29>, /* TDM_DO */
					      <30>, /* TDM_DI */
					      <31>; /* TDM_DCL */
				intel,function = "tdm";
				intel,mux = <EQBR_MUX_3>;
				intel,groups = "tdm";
			};

			pinctrl_mdio_l: mdio_l {
				intel,pins =  <42>, /* MDC0 */
					      <43>; /* MDIO0 */
				intel,function = "mdio_l";
				intel,mux = <EQBR_MUX_1>;
				intel,groups = "mdio_l";
				intel,open-drain = <1>;
			};

			pinctrl_mdio_r: mdio_r {
				intel,pins =  <32>, /* MDC1 */
					      <33>; /* MDIO1 */
				intel,function = "mdio_r";
				intel,mux = <EQBR_MUX_1>;
				intel,groups = "mdio_r";
				intel,open-drain = <1>;
			};

			pinctrl_spi0: spi0 {
				intel,pins =  <16>, /* SPI0_CLK */
					      <17>, /* SPI0_TX */
					      <18>; /* SPI0_RX */
				intel,function = "spi0";
				intel,mux = <EQBR_MUX_1>;
				intel,groups = "spi0";
			};

			pinctrl_spi1: spi1 {
				intel,pins =  <10>, /* SPI1_CLK */
					      <11>, /* SPI1_TX */
					      <19>; /* SPI1_RX */
				intel,function = "spi1";
				intel,mux = <EQBR_MUX_1>;
				intel,groups = "spi1";
			};

			pinctrl_ledc: ledc {
				intel,pins =  <4>, /* LED_SH */
					      <5>, /* LED_ST */
					      <6>; /* LED_D */
				intel,function = "led";
				intel,mux = <EQBR_MUX_1>;
				intel,groups = "led";
			};

			pinctrl_i2c0: i2c0 {
				intel,pins =  <21>, /* I2C0_SCL */
					      <22>; /* I2C0_SDA */
				intel,function = "i2c0";
				intel,mux = <EQBR_MUX_1>;
				intel,groups = "i2c0";
				intel,open-drain = <1>;
			};

			pinctrl_usb0_default: usb0_default {
				intel,pins = <7>;
				intel,function = "usb0_default";
				intel,mux = <EQBR_MUX_0>;
				intel,groups = "usb0_default";
			};

			pinctrl_usb0_idle: usb0_idle {
				intel,pins = <7>;
				intel,function = "usb0_idle";
				intel,mux = <EQBR_MUX_3>;
				intel,groups = "usb0_idle";
			};

			pinctrl_usb1_default: usb1_default {
				intel,pins = <2>;
				intel,function = "usb1_default";
				intel,mux = <EQBR_MUX_0>;
				intel,groups = "usb1_default";
			};

			pinctrl_usb1_idle: usb1_idle {
				intel,pins = <2>;
				intel,function = "usb1_idle";
				intel,mux = <EQBR_MUX_3>;
				intel,groups = "usb1_idle";
			};
		};

		gpio0: gpio@c00000 {
			gpio-controller;
			#gpio-cells = <2>;
			reg = <0xc00000 0x80>;
			interrupt-controller;
			#interrupt-cells = <2>;
			interrupt-parent = <&gic>;
			interrupts = <GIC_SHARED 172 IRQ_TYPE_LEVEL_HIGH>;
			ngpios = <32>;
			gpio-ranges = <&pinctrl 0 0 32>;
		};

		gpio1: gpio@c00100 {
			gpio-controller;
			#gpio-cells = <2>;
			reg = <0xc00100 0x80>;
			interrupt-controller;
			#interrupt-cells = <2>;
			interrupt-parent = <&gic>;
			interrupts = <GIC_SHARED 173 IRQ_TYPE_LEVEL_HIGH>;
			ngpios = <30>;
			gpio-ranges = <&pinctrl 0 32 30>;
		};

		ssogpio: ssogpio@d00000 {
			compatible = "intel,sso-gpio", "syscon", "simple-mfd";
			status = "disabled";
			gpio-controller;
			#gpio-cells = <2>;
			reg = <0xd00000 0x2cc>;
			ngpios = <16>;
			pinctrl-names = "default";
			pinctrl-0 = <&pinctrl_ledc>;
			clocks = <&clkgate1 GATE_SSO_CLK>;
			clock-names = "sso";

			ssoled:ssoled {
				compatible = "intel,sso-led";
				status = "disabled";
				clocks = <&afeclk>;
				clock-names = "fpid";
				intel,gptc-clkrate = <200000000>;
			};
		};
	};

	ssx6@12000000 {
		#address-cells = <1>;
		#size-cells = <1>;
		compatible = "lantiq,ssx", "simple-bus";
		reg = <0x12000000 0x2000000>;
		ranges = <0x0 0x12000000 0x02000000>;

		gcr@300000 {
			compatible = "lantiq,gcr-grx500";
			reg = <0x300000 0x8000>;
		};

		cpc@310000 {
			compatible = "lantiq,cpc-grx500";
			reg = <0x310000 0x6000>;
		};

		gic: gic@320000 {
			compatible = "mti,gic";
			reg = <0x320000 0x20000>;
			interrupt-controller;
			#interrupt-cells = <3>;
			/*
			 * Declare the interrupt-parent even though the mti,gic
			 * binding doesn't require it, such that the kernel can
			 * figure out that cpu_intc is the root interrupt
			 * controller & should be probed first.
			 */
			interrupt-parent = <&cpu_intc>;
			mti,reserved-ipi-vectors = <56 8>;
			mti,reserved-list = <20 21 85>;
			timer {
				compatible = "mti,gic-timer";
				interrupts = <GIC_LOCAL 1 IRQ_TYPE_NONE>;
				clocks = <&cpuclk>;
				clock-names = "cpuclk";
			};
		};

		gcrcus@3f0000 {
			compatible = "lantiq,gcrcus-grx500";
			reg = <0x3f0000 0x200>;
		};

		watchdog@0,0 {
			#interrupt-cells = <1>;
			compatible = "lantiq,grx500wdt";
			reg = <0 0>;
			interrupt-parent = <&gic>;
			interrupts = <GIC_LOCAL 0 IRQ_TYPE_NONE>;
			timeout-sec = <5>;
			lantiq,wdt-rcu = <&rcu0>;
			clocks = <&cpuclk>;
			clock-names = "freq";
		};
	};

	ssx7@a0000000 {
		#address-cells = <1>;
		#size-cells = <1>;
		compatible = "lantiq,ssx", "simple-bus";
		reg = <0xa0000000 0x20000000>;
		ranges = <0x0 0xa0000000 0x20000000>;

		mpe: mpe@0 {
			#address-cells = <1>;
			#size-cells = <1>;
			compatible = "lantiq,mpe-xrx500";
			reg = <0x0 0x200000>;
			dtlk_vpe_num = <1>;
			interrupt-parent = <&gic>;
			interrupts = <GIC_SHARED 246 IRQ_TYPE_EDGE_RISING>;
		};

		toe: toe@2000000 {
			#address-cells = <1>;
			#size-cells = <1>;
			compatible = "lantiq,toe-xrx500";
			reg = <0x2000000 0x10000
				   0x2013000 0x4000>;
			interrupt-parent = <&gic>;
			interrupts = <GIC_SHARED 71 IRQ_TYPE_LEVEL_HIGH>,
				<GIC_SHARED 72 IRQ_TYPE_LEVEL_HIGH>,
				<GIC_SHARED 73 IRQ_TYPE_LEVEL_HIGH>,
				<GIC_SHARED 74 IRQ_TYPE_LEVEL_HIGH>,
				<GIC_SHARED 75 IRQ_TYPE_LEVEL_HIGH>,
				<GIC_SHARED 182 IRQ_TYPE_LEVEL_HIGH>,
				<GIC_SHARED 183 IRQ_TYPE_LEVEL_HIGH>,
				<GIC_SHARED 184 IRQ_TYPE_LEVEL_HIGH>,
				<GIC_SHARED 185 IRQ_TYPE_LEVEL_HIGH>,
				<GIC_SHARED 186 IRQ_TYPE_LEVEL_HIGH>,
				<GIC_SHARED 187 IRQ_TYPE_LEVEL_HIGH>,
				<GIC_SHARED 188 IRQ_TYPE_LEVEL_HIGH>,
				<GIC_SHARED 189 IRQ_TYPE_LEVEL_HIGH>,
				<GIC_SHARED 190 IRQ_TYPE_LEVEL_HIGH>,
				<GIC_SHARED 191 IRQ_TYPE_LEVEL_HIGH>;
		};

		mcpy: mcpy@2800000 {
			#address-cells = <1>;
			#size-cells = <1>;
			compatible = "lantiq,mcpy-xrx500";
			reg = <0x2800000 0x800000>;
			interrupt-parent = <&gic>;
			interrupts = <GIC_SHARED 192 IRQ_TYPE_EDGE_RISING>,
				<GIC_SHARED 193 IRQ_TYPE_EDGE_RISING>,
				<GIC_SHARED 194 IRQ_TYPE_EDGE_RISING>,
				<GIC_SHARED 195 IRQ_TYPE_EDGE_RISING>,
				<GIC_SHARED 196 IRQ_TYPE_EDGE_RISING>,
				<GIC_SHARED 197 IRQ_TYPE_EDGE_RISING>,
				<GIC_SHARED 198 IRQ_TYPE_EDGE_RISING>,
				<GIC_SHARED 199 IRQ_TYPE_EDGE_RISING>,
				<GIC_SHARED 200 IRQ_TYPE_LEVEL_HIGH>,
				<GIC_SHARED 201 IRQ_TYPE_LEVEL_HIGH>,
				<GIC_SHARED 202 IRQ_TYPE_LEVEL_HIGH>,
				<GIC_SHARED 203 IRQ_TYPE_LEVEL_HIGH>,
				<GIC_SHARED 204 IRQ_TYPE_LEVEL_HIGH>,
				<GIC_SHARED 205 IRQ_TYPE_LEVEL_HIGH>,
				<GIC_SHARED 206 IRQ_TYPE_LEVEL_HIGH>,
				<GIC_SHARED 207 IRQ_TYPE_LEVEL_HIGH>,
				<GIC_SHARED 208 IRQ_TYPE_LEVEL_HIGH>;
			interrupt-names = "yld0", "yld1", "yld2", "yld3", "yld4", "yld5", "yld6", "yld7", "irq0", "irq1", "irq2", "irq3", "irq4", "irq5", "irq6", "irq7";
			/* Prio (1 is high), reserved for which VPE. (-1 NO reserve), trank size, irq_interval,  Enable (1 is En) */
			/* Trunk size:  -1 - Default Value, 0-"512B", 1-"1KB", 2-"2KB", 3-"4KB", 4-"8KB", 5-"16KB", 6-"32KB", 7-"64KB" */
			/* IRQ interval: 0 - Default Value> */
			/* mcpy ch id from 0 to 7, default setting please refer to the mcpy driver source code */
			/* lantiq,mcpy-ch0 = <1 0 -1 0 1>;  set mcpy ch0 to high prio, reserved for vpe 0, defaut trunk size, default irq_interval, enable*/
			lantiq,mcpy-minlen = <64>;
			lantiq,umt0-dmacid = <7>;
			lantiq,umt1-dmacid = <8>;
			lantiq,umt2-dmacid = <9>;
			lantiq,umt3-dmacid = <10>;
			clocks = <&pll0aclk NGI_CLK>;
			clock-names = "freq";
		};
	};

	thermal-zones {
		cpu_thermal: cpu-thermal {
			polling-delay-passive = <500>; /* milliseconds */
			polling-delay = <1000>; /* milliseconds */

			thermal-sensors = <&ts>;

			trips {
				cpu_alert0: cpu-alert0 {
					temperature = <115000>; /* millicelsius */
					hysteresis = <5000>; /* millicelsius */
					type = "passive";
				};
				cpu_crit: cpu-crit {
					temperature = <125000>; /* millicelsius */
					hysteresis = <10000>; /* millicelsius */
					type = "critical";
				};
			};

			cooling_maps: cooling-maps {
				map0 {
					trip = <&cpu_alert0>;
					cooling-device = <&cpu0 2 2>;
				};
				map1 {
					trip = <&cpu_alert0>;
					cooling-device = <&eth 0 4>;
				};
			};
		};
	};
};
